VERSION ""

NS_ :

BS_:

BU_: ADAS RADAR NEO XXX

BO_ 768 VEHICLE_STATE: 8 ADAS
 SG_ SET_ME_XF9 : 7|8@0+ (1,0) [0|255] "" Vector__XXX
 SG_ VEHICLE_SPEED : 15|8@0+ (1,0) [0|255] "kph" Vector__XXX

BO_ 769 VEHICLE_STATE2: 8 ADAS
 SG_ SET_ME_0F18510 : 7|28@0+ (1,0) [0|268435455] "" Vector__XXX
 SG_ SET_ME_25A0000 : 27|28@0+ (1,0) [0|268435455] "" Vector__XXX

BO_ 1024 XXX_100: 8 RADAR
 SG_ RADAR_STATUS : 7|8@0+ (1,0) [0|255] "" NEO

BO_ 1040 XXX_101: 8 RADAR

BO_ 1041 XXX_102: 8 RADAR

BO_ 1042 XXX_103: 8 RADAR

BO_ 1043 XXX_104: 8 RADAR

BO_ 1044 XXX_105: 8 RADAR

BO_ 1045 XXX_106: 8 RADAR

BO_ 1046 XXX_107: 8 RADAR

BO_ 1047 XXX_108: 8 RADAR

BO_ 1056 XXX_109: 8 RADAR

BO_ 1057 XXX_110: 8 RADAR

BO_ 1058 XXX_111: 8 RADAR

BO_ 1059 XXX_112: 8 RADAR

BO_ 1060 XXX_113: 8 RADAR

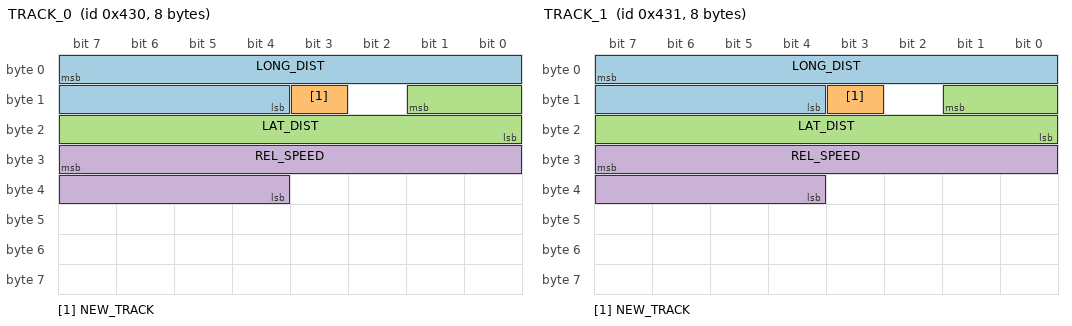
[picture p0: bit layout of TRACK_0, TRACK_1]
BO_ 1072 TRACK_0: 8 RADAR
 SG_ LONG_DIST : 7|12@0+ (0.0625,0) [0|255.5] "m"  NEO
 SG_ NEW_TRACK : 11|1@0+ (1,0) [0|1] ""  NEO
 SG_ LAT_DIST : 9|10@0- (0.0625,0) [0|63.5] "m"  NEO
 SG_ REL_SPEED : 31|12@0- (0.03125,0) [0|127.5] "m/s"  NEO

BO_ 1073 TRACK_1: 8 RADAR
 SG_ LONG_DIST : 7|12@0+ (0.0625,0) [0|255.5] "m"  NEO
 SG_ NEW_TRACK : 11|1@0+ (1,0) [0|1] ""  NEO
 SG_ LAT_DIST : 9|10@0- (0.0625,0) [0|63.5] "m"  NEO
 SG_ REL_SPEED : 31|12@0- (0.03125,0) [0|127.5] "m/s"  NEO

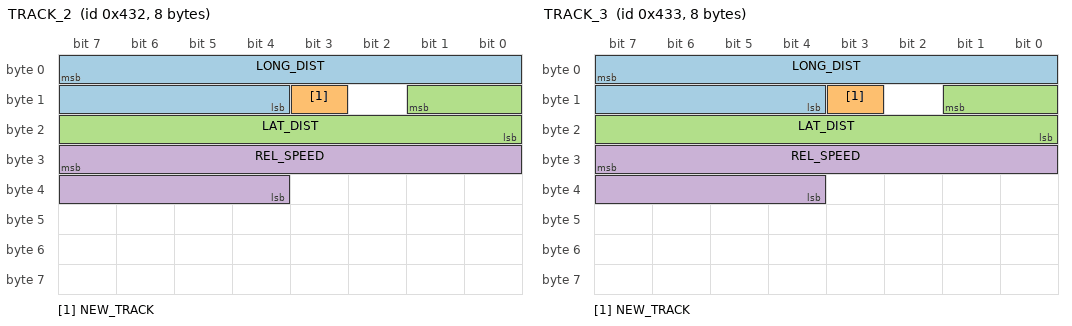
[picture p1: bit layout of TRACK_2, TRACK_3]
BO_ 1074 TRACK_2: 8 RADAR
 SG_ LONG_DIST : 7|12@0+ (0.0625,0) [0|255.5] "m"  NEO
 SG_ NEW_TRACK : 11|1@0+ (1,0) [0|1] ""  NEO
 SG_ LAT_DIST : 9|10@0- (0.0625,0) [0|63.5] "m"  NEO
 SG_ REL_SPEED : 31|12@0- (0.03125,0) [0|127.5] "m/s"  NEO

BO_ 1075 TRACK_3: 8 RADAR
 SG_ LONG_DIST : 7|12@0+ (0.0625,0) [0|255.5] "m"  NEO
 SG_ NEW_TRACK : 11|1@0+ (1,0) [0|1] ""  NEO
 SG_ LAT_DIST : 9|10@0- (0.0625,0) [0|63.5] "m"  NEO
 SG_ REL_SPEED : 31|12@0- (0.03125,0) [0|127.5] "m/s"  NEO

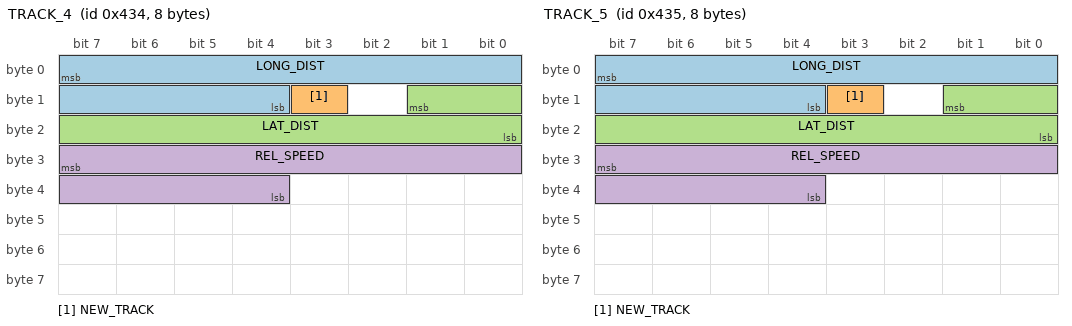
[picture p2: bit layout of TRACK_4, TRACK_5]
BO_ 1076 TRACK_4: 8 RADAR
 SG_ LONG_DIST : 7|12@0+ (0.0625,0) [0|255.5] "m"  NEO
 SG_ NEW_TRACK : 11|1@0+ (1,0) [0|1] ""  NEO
 SG_ LAT_DIST : 9|10@0- (0.0625,0) [0|63.5] "m"  NEO
 SG_ REL_SPEED : 31|12@0- (0.03125,0) [0|127.5] "m/s"  NEO

BO_ 1077 TRACK_5: 8 RADAR
 SG_ LONG_DIST : 7|12@0+ (0.0625,0) [0|255.5] "m"  NEO
 SG_ NEW_TRACK : 11|1@0+ (1,0) [0|1] ""  NEO
 SG_ LAT_DIST : 9|10@0- (0.0625,0) [0|63.5] "m"  NEO
 SG_ REL_SPEED : 31|12@0- (0.03125,0) [0|127.5] "m/s"  NEO

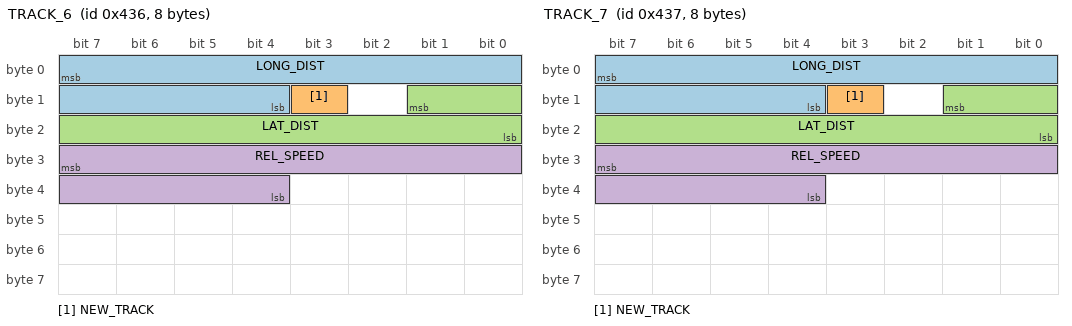
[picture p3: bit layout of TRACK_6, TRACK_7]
BO_ 1078 TRACK_6: 8 RADAR
 SG_ LONG_DIST : 7|12@0+ (0.0625,0) [0|255.5] "m"  NEO
 SG_ NEW_TRACK : 11|1@0+ (1,0) [0|1] ""  NEO
 SG_ LAT_DIST : 9|10@0- (0.0625,0) [0|63.5] "m"  NEO
 SG_ REL_SPEED : 31|12@0- (0.03125,0) [0|127.5] "m/s"  NEO

BO_ 1079 TRACK_7: 8 RADAR
 SG_ LONG_DIST : 7|12@0+ (0.0625,0) [0|255.5] "m"  NEO
 SG_ NEW_TRACK : 11|1@0+ (1,0) [0|1] ""  NEO
 SG_ LAT_DIST : 9|10@0- (0.0625,0) [0|63.5] "m"  NEO
 SG_ REL_SPEED : 31|12@0- (0.03125,0) [0|127.5] "m/s"  NEO

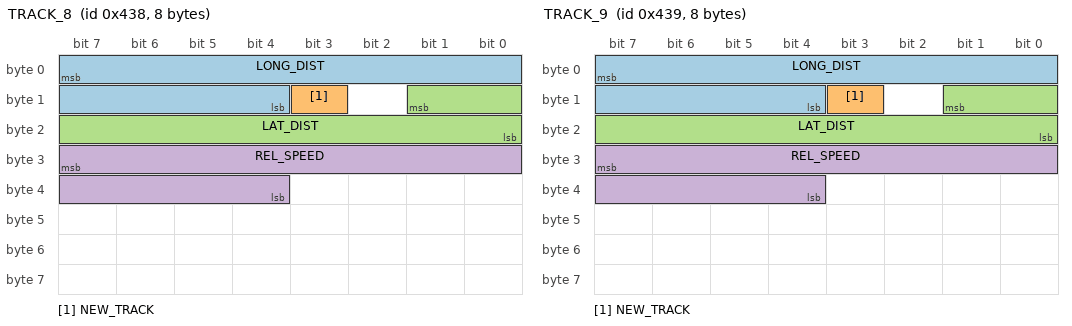
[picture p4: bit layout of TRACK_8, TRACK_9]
BO_ 1080 TRACK_8: 8 RADAR
 SG_ LONG_DIST : 7|12@0+ (0.0625,0) [0|255.5] "m"  NEO
 SG_ NEW_TRACK : 11|1@0+ (1,0) [0|1] ""  NEO
 SG_ LAT_DIST : 9|10@0- (0.0625,0) [0|63.5] "m"  NEO
 SG_ REL_SPEED : 31|12@0- (0.03125,0) [0|127.5] "m/s"  NEO

BO_ 1081 TRACK_9: 8 RADAR
 SG_ LONG_DIST : 7|12@0+ (0.0625,0) [0|255.5] "m"  NEO
 SG_ NEW_TRACK : 11|1@0+ (1,0) [0|1] ""  NEO
 SG_ LAT_DIST : 9|10@0- (0.0625,0) [0|63.5] "m"  NEO
 SG_ REL_SPEED : 31|12@0- (0.03125,0) [0|127.5] "m/s"  NEO

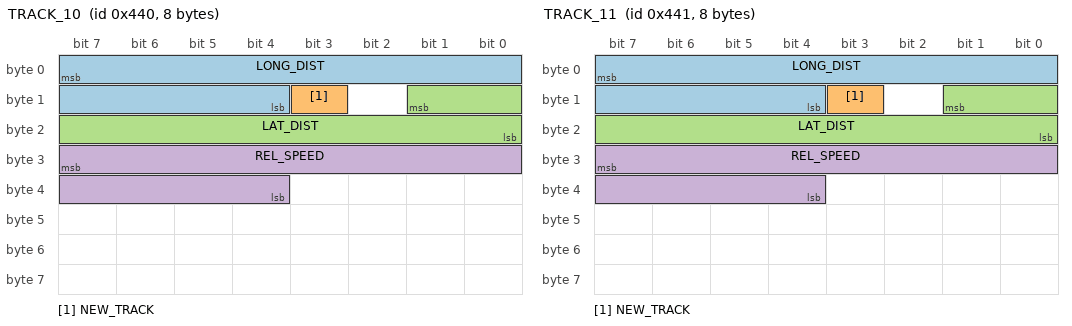
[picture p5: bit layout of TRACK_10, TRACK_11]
BO_ 1088 TRACK_10: 8 RADAR
 SG_ LONG_DIST : 7|12@0+ (0.0625,0) [0|255.5] "m"  NEO
 SG_ NEW_TRACK : 11|1@0+ (1,0) [0|1] ""  NEO
 SG_ LAT_DIST : 9|10@0- (0.0625,0) [0|63.5] "m"  NEO
 SG_ REL_SPEED : 31|12@0- (0.03125,0) [0|127.5] "m/s"  NEO

BO_ 1089 TRACK_11: 8 RADAR
 SG_ LONG_DIST : 7|12@0+ (0.0625,0) [0|255.5] "m"  NEO
 SG_ NEW_TRACK : 11|1@0+ (1,0) [0|1] ""  NEO
 SG_ LAT_DIST : 9|10@0- (0.0625,0) [0|63.5] "m"  NEO
 SG_ REL_SPEED : 31|12@0- (0.03125,0) [0|127.5] "m/s"  NEO

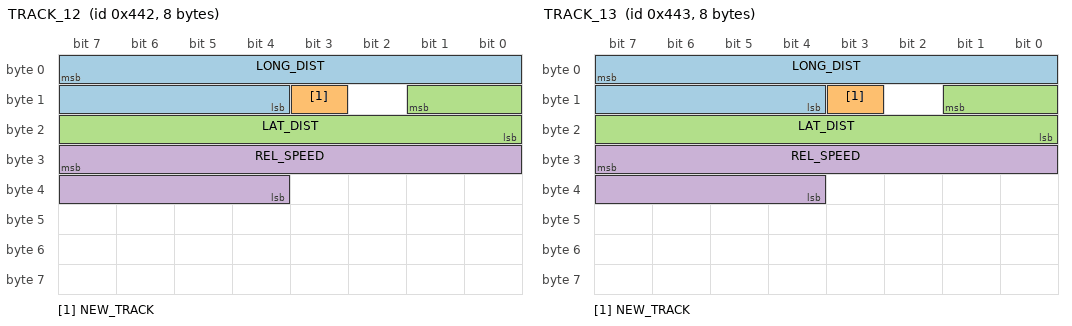
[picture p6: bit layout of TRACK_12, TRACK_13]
BO_ 1090 TRACK_12: 8 RADAR
 SG_ LONG_DIST : 7|12@0+ (0.0625,0) [0|255.5] "m"  NEO
 SG_ NEW_TRACK : 11|1@0+ (1,0) [0|1] ""  NEO
 SG_ LAT_DIST : 9|10@0- (0.0625,0) [0|63.5] "m"  NEO
 SG_ REL_SPEED : 31|12@0- (0.03125,0) [0|127.5] "m/s"  NEO

BO_ 1091 TRACK_13: 8 RADAR
 SG_ LONG_DIST : 7|12@0+ (0.0625,0) [0|255.5] "m"  NEO
 SG_ NEW_TRACK : 11|1@0+ (1,0) [0|1] ""  NEO
 SG_ LAT_DIST : 9|10@0- (0.0625,0) [0|63.5] "m"  NEO
 SG_ REL_SPEED : 31|12@0- (0.03125,0) [0|127.5] "m/s"  NEO

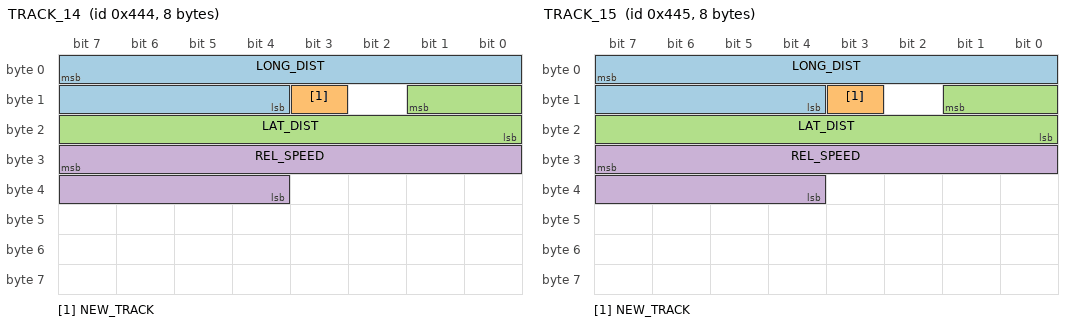
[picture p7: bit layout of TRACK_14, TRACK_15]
BO_ 1092 TRACK_14: 8 RADAR
 SG_ LONG_DIST : 7|12@0+ (0.0625,0) [0|255.5] "m"  NEO
 SG_ NEW_TRACK : 11|1@0+ (1,0) [0|1] ""  NEO
 SG_ LAT_DIST : 9|10@0- (0.0625,0) [0|63.5] "m"  NEO
 SG_ REL_SPEED : 31|12@0- (0.03125,0) [0|127.5] "m/s"  NEO

BO_ 1093 TRACK_15: 8 RADAR
 SG_ LONG_DIST : 7|12@0+ (0.0625,0) [0|255.5] "m"  NEO
 SG_ NEW_TRACK : 11|1@0+ (1,0) [0|1] ""  NEO
 SG_ LAT_DIST : 9|10@0- (0.0625,0) [0|63.5] "m"  NEO
 SG_ REL_SPEED : 31|12@0- (0.03125,0) [0|127.5] "m/s"  NEO

BO_ 1279 XXX_114: 8 RADAR

BO_ 1280 XXX_115: 8 RADAR

BO_ 1296 XXX_116: 8 RADAR

BO_ 1297 XXX_117: 8 RADAR

BO_TX_BU_ 768 : NEO,ADAS;
BO_TX_BU_ 769 : NEO,ADAS;

CM_ SG_ 1024 RADAR_STATUS "need to find out more diagnostic values";
VAL_ 1024 RADAR_STATUS 121 "ok" 110 "faulted";
